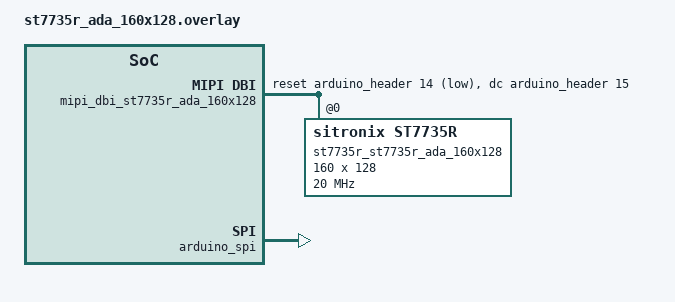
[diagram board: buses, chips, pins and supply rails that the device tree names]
/*
 * Copyright (c) 2020, Kim Bøndergaard, <kim@fam-boendergaard.dk>
 *
 * SPDX-License-Identifier: Apache-2.0
 */

#include <zephyr/dt-bindings/mipi_dbi/mipi_dbi.h>

/ {
	chosen {
		zephyr,display = &st7735r_st7735r_ada_160x128;
	};

	mipi_dbi_st7735r_ada_160x128 {
		compatible = "zephyr,mipi-dbi-spi";
		spi-dev = <&arduino_spi>;
		dc-gpios = <&arduino_header 15 GPIO_ACTIVE_HIGH>;	/* D9 */
		reset-gpios = <&arduino_header 14 GPIO_ACTIVE_LOW>;	/* D8 */
		#address-cells = <1>;
		#size-cells = <0>;

		st7735r_st7735r_ada_160x128: st7735r@0 {
			compatible = "sitronix,st7735r";
			mipi-max-frequency = <20000000>;
			mipi-mode = "MIPI_DBI_MODE_SPI_4WIRE";
			reg = <0>;
			width = <160>;
			height = <128>;
			x-offset = <0>;
			y-offset = <0>;
			madctl = <0x60>;
			colmod = <0x55>;
			vmctr1 = <0x0e>;
			pwctr1 = [a2 02 84];
			pwctr2 = [c5];
			pwctr3 = [0a 00];
			pwctr4 = [8a 2a];
			pwctr5 = [8a ee];
			frmctr1 = [01 2c 2d];
			frmctr2 = [01 2c 2d];
			frmctr3 = [01 2c 2d 01 2c 2d];
			gamctrp1 = [02 1c 07 12 37 32 29 2d 29 25 2b 39 00 01 03 10];
			gamctrn1 = [03 1d 07 06 2e 2c 29 2d 2e 2e 37 3f 00 00 02 10];
		};
	};
};

&arduino_spi {
	status = "okay";
	cs-gpios = <&arduino_header 16 GPIO_ACTIVE_LOW>;	/* D10 */
};
